AUTOSAR XML (schema 00049)
# Copyright (c) 2018 Vector Informatik GmbH.
standard types defined: boolean, uint16, uint32, uint8
package /VehicleProject
  system System
package /TP
  lin tp config LINISO17987: communication-cluster=LINISO17987
    tp address TA_0x0002: tp-address=2
    tp address TA_0x0003: tp-address=3
    tp address TA_0x007E: tp-address=126
    tp-connections:
      data-pdu=MasterReq_Tp, lin-tp-n-sdu=MasterReq, multicast=TA_0x007E, receiver=[TN_0x0002_Motor1, TN_0x0003_Motor2], transmitter=TN_Master
      data-pdu=SlaveResp_Tp, flow-control=MasterReq_Tp, lin-tp-n-sdu=SlaveResp_Motor1, receiver=TN_Master, transmitter=TN_0x0002_Motor1
      data-pdu=SlaveResp_Tp, flow-control=MasterReq_Tp, lin-tp-n-sdu=SlaveResp_Motor2, receiver=TN_Master, transmitter=TN_0x0003_Motor2
      data-pdu=MasterReq_Tp, flow-control=SlaveResp_Tp, lin-tp-n-sdu=MasterReq_Motor1, receiver=TN_0x0002_Motor1, transmitter=TN_Master
      data-pdu=MasterReq_Tp, flow-control=SlaveResp_Tp, lin-tp-n-sdu=MasterReq_Motor2, receiver=TN_0x0003_Motor2, transmitter=TN_Master
    lin tp node TN_0x0002_Motor1: connector=Motor1/CN_LINISO17987, tp-address=TA_0x0002
    lin tp node TN_0x0003_Motor2: connector=Motor2/CN_LINISO17987, tp-address=TA_0x0003
    lin tp node TN_Master: connector=SeatECU/CN_LINISO17987
package /Cluster
  lin cluster LINISO17987: baudrate=19200, protocol-name=LIN, protocol-version=ISO17987  # /*************************************************************************************/ // // Description: LIN Description file created using Vector's DaVinci Network Designer // Created: 07 Sep 2007 14:37:29 // Author: Vector Informatik GmbH // Version: 0.1 // /*************************************************************************************/
    lin physical channel CHNL: comm-connectors=[Motor1/CN_LINISO17987, Motor2/CN_LINISO17987, SeatECU/CN_LINISO17987]
      frame ETF_MotorStates: id 0x3A, from Motor1 Motor2, to SeatECU, frame-length=3, collision-resolving-schedule=ETFCollisionResolving, lin-unconditional-frame=[Motor1State_Event, Motor2State_Event], lin-checksum=ENHANCED
      frame MasterReq: id 0x3C, from SeatECU, to Motor1 Motor2, frame-length=8, lin-checksum=CLASSIC
        n pdu MasterReq_Tp: length=8
      frame Motor1Control: id 0x30, from SeatECU, to Motor1, frame-length=1, lin-checksum=ENHANCED
        pdu Motor1Control: length=1, transmission-mode-true-timing=event-controlled-timing={number-of-repetitions=0, repetition-period=0}, unused-bit-pattern=255
          signal Motor1Selection_oMotor1Control: start 0, 2 bit, little-endian, i-signal-type=PRIMITIVE, init-value=0, base-type=uint8, compu {identical}, range raw 0..3, transfer-property=TRIGGERED-WITHOUT-REPETITION, to Motor1
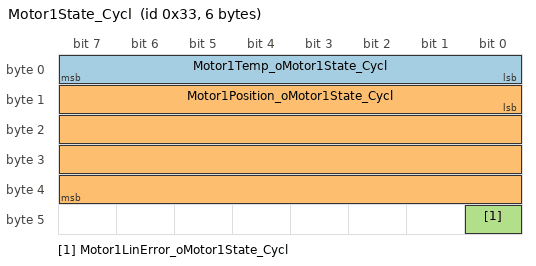
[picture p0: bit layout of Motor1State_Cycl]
      frame Motor1State_Cycl: id 0x33, from Motor1, to SeatECU, frame-length=6, lin-checksum=ENHANCED
        pdu Motor1State_Cycl: length=6, unused-bit-pattern=255
          signal Motor1Temp_oMotor1State_Cycl: start 0, 8 bit, little-endian, i-signal-type=PRIMITIVE, init-value=5, base-type=uint8, compu {phys=raw*0.5-20 for raw 0..80; unit Degree}, range raw 0..80, unit=Degree, to SeatECU
          signal Motor1Position_oMotor1State_Cycl: start 8, 32 bit, little-endian, i-signal-type=PRIMITIVE, init-value=0, base-type=uint32, compu {identical}, range raw 0..4294967295, to SeatECU
          signal Motor1LinError_oMotor1State_Cycl: start 40, 1 bit, little-endian, i-signal-type=PRIMITIVE, init-value=0, base-type=boolean, compu {identical}, range raw 0..1, to SeatECU
      frame Motor1State_Event: id 0x36, from Motor1, to SeatECU, frame-length=3, lin-checksum=ENHANCED
        pdu Motor1State_Event: length=3, unused-bit-pattern=255
          signal Motor1ErrorCode_oMotor1State_Event: start 8, 8 bit, little-endian, i-signal-type=PRIMITIVE, init-value=5, base-type=uint8, compu {identical}, range raw 0..255, to SeatECU
          signal Motor1ErrorValue_oMotor1State_Event: start 16, 8 bit, little-endian, i-signal-type=PRIMITIVE, init-value=1, base-type=uint8, compu {identical}, range raw 0..255, to SeatECU
      frame Motor2Control: id 0x31, from SeatECU, to Motor2, frame-length=1, lin-checksum=ENHANCED
        pdu Motor2Control: length=1, transmission-mode-true-timing=event-controlled-timing={number-of-repetitions=0, repetition-period=0}, unused-bit-pattern=255
          signal Motor2Selection_oMotor2Control: start 0, 2 bit, little-endian, i-signal-type=PRIMITIVE, init-value=0, base-type=uint8, compu {identical}, range raw 0..3, transfer-property=TRIGGERED-WITHOUT-REPETITION, to Motor2
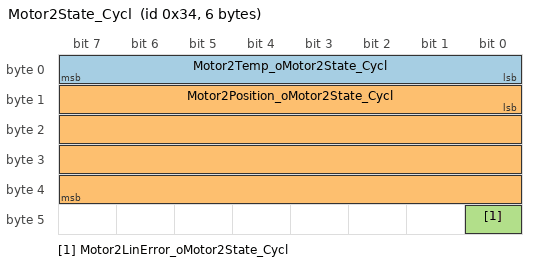
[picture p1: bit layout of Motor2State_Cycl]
      frame Motor2State_Cycl: id 0x34, from Motor2, to SeatECU, frame-length=6, lin-checksum=ENHANCED
        pdu Motor2State_Cycl: length=6, unused-bit-pattern=255
          signal Motor2Temp_oMotor2State_Cycl: start 0, 8 bit, little-endian, i-signal-type=PRIMITIVE, init-value=0, base-type=uint8, compu {phys=raw*0.5-20 for raw 0..80; unit Degree}, range raw 0..80, unit=Degree, to SeatECU
          signal Motor2Position_oMotor2State_Cycl: start 8, 32 bit, little-endian, i-signal-type=PRIMITIVE, init-value=0, base-type=uint32, compu {identical}, range raw 0..4294967295, to SeatECU
          signal Motor2LinError_oMotor2State_Cycl: start 40, 1 bit, little-endian, i-signal-type=PRIMITIVE, init-value=0, base-type=boolean, compu {identical}, range raw 0..1, to SeatECU
      frame Motor2State_Event: id 0x37, from Motor2, to SeatECU, frame-length=3, lin-checksum=ENHANCED
        pdu Motor2State_Event: length=3, unused-bit-pattern=255
          signal Motor2ErrorCode_oMotor2State_Event: start 8, 8 bit, little-endian, i-signal-type=PRIMITIVE, init-value=2, base-type=uint8, compu {identical}, range raw 0..255, to SeatECU
          signal Motor2ErrorValue_oMotor2State_Event: start 16, 8 bit, little-endian, i-signal-type=PRIMITIVE, init-value=4, base-type=uint8, compu {identical}, range raw 0..255, to SeatECU
      frame MotorsControl: id 0x2D, from SeatECU, to Motor1 Motor2, frame-length=2, lin-checksum=ENHANCED
        pdu MotorsControl: length=2, unused-bit-pattern=255
          signal MotorDirection_oMotorsControl: start 0, 2 bit, little-endian, i-signal-type=PRIMITIVE, init-value=0, base-type=uint8, compu {identical}, range raw 0..3, to Motor1 Motor2
          signal MotorSpeed_oMotorsControl: start 2, 10 bit, little-endian, i-signal-type=PRIMITIVE, init-value=0, base-type=uint16, compu {identical}, range raw 0..1023, unit=rpm, to Motor1 Motor2
      frame SlaveResp: id 0x3D, from Motor1 Motor2, to SeatECU, frame-length=8, lin-checksum=CLASSIC
        n pdu SlaveResp_Tp: length=8
      frame SporadicControlFrame: from SeatECU, to Motor1 Motor2, frame-length=1, substituted-frame=[Motor1Control, Motor2Control]
      pdu triggering PT_MasterReq: pdu=MasterReq, from SeatECU, to Motor1 Motor2
      pdu triggering PT_MasterReq_Motor1: pdu=MasterReq_Motor1, from SeatECU, to Motor1
      pdu triggering PT_MasterReq_Motor2: pdu=MasterReq_Motor2, from SeatECU, to Motor2
      pdu triggering PT_SlaveResp_Motor1: pdu=SlaveResp_Motor1, from Motor1, to SeatECU
      pdu triggering PT_SlaveResp_Motor2: pdu=SlaveResp_Motor2, from Motor2, to SeatECU
      5 x lin schedule table, all with run-mode=RUN-CONTINUOUS:
        NormalTable
          table-entrys:
            delay=0.05, position-in-table=0, frame-triggering=FT_MotorsControl
            delay=0.05, position-in-table=1, frame-triggering=FT_Motor1State_Cycl
            delay=0.05, position-in-table=2, frame-triggering=FT_Motor2State_Cycl
            delay=0.05, position-in-table=3, frame-triggering=FT_ETF_MotorStates
            delay=0.02, position-in-table=4, frame-triggering=FT_SporadicControlFrame
        ETFCollisionResolving
          table-entrys:
            delay=0.05, position-in-table=0, frame-triggering=FT_Motor1State_Event
            delay=0.05, position-in-table=1, frame-triggering=FT_Motor2State_Event
        InitTable: table-entrys={assign-nad={delay=0.01, position-in-table=0, assigned-controller=Motor1/CT_LINISO17987, new-nad=2}, application-entry={delay=0.01, position-in-table=1, frame-triggering=FT_SlaveResp}, assign-nad={delay=0.01, position-in-table=2, assigned-controller=Motor2/CT_LINISO17987, new-nad=3}, application-entry={delay=0.01, position-in-table=3, frame-triggering=FT_SlaveResp}, assign-frame-id-range={delay=0.01, position-in-table=4, assigned-controller=Motor1/CT_LINISO17987, frame-pids=[{index=0, pid=173}, {index=1, pid=240}, {index=2, pid=115}, {index=3, pid=118}], start-index=0}, assign-frame-id-range={delay=0.01, position-in-table=5, assigned-controller=Motor1/CT_LINISO17987, frame-pids=[{index=4, pid=186}, {index=5, pid=255}, {index=6, pid=255}, {index=7, pid=255}], start-index=4}, assign-frame-id-range={delay=0.01, position-in-table=6, assigned-controller=Motor2/CT_LINISO17987, frame-pids=[{index=0, pid=173}, {index=1, pid=177}, {index=2, pid=180}, {index=3, pid=55}], start-index=0}, assign-frame-id-range={delay=0.01, position-in-table=7, assigned-controller=Motor2/CT_LINISO17987, frame-pids=[{index=4, pid=186}, {index=5, pid=255}, {index=6, pid=255}, {index=7, pid=255}], start-index=4}}
        MasterReqTable: application-entry{delay=0.01, position-in-table=0, frame-triggering=FT_MasterReq}
        SlaveRespTable: application-entry{delay=0.01, position-in-table=0, frame-triggering=FT_SlaveResp}
package /ECU
  ecu instance Motor1: associated-com-i-pdu-group=[Motor1_Rx, Motor1_Tx]
    lin slave CT_LINISO17987: protocol-version=ISO17987, assign-nad=false, configured-nad=2, function-id=1, initial-nad=10, lin-error-response=ST_Motor1LinError_oMotor1State_Cycl, nas-timeout=1000, supplier-id=30, variant-id=0
    lin communication connector CN_LINISO17987: comm-controller=Motor1/CT_LINISO17987, initial-nad=10
      lin-ordered-configurable-frames:
        frame=MotorsControl, index=0
        frame=Motor1Control, index=1
        frame=Motor1State_Cycl, index=2
        frame=Motor1State_Event, index=3
        frame=ETF_MotorStates, index=4
  ecu instance Motor2: associated-com-i-pdu-group=[Motor2_Rx, Motor2_Tx]
    lin slave CT_LINISO17987: protocol-version=ISO17987, assign-nad=false, configured-nad=3, function-id=11, initial-nad=12, lin-error-response=ST_Motor2LinError_oMotor2State_Cycl, nas-timeout=1000, supplier-id=46, variant-id=1
    lin communication connector CN_LINISO17987: comm-controller=Motor2/CT_LINISO17987, initial-nad=12
      lin-ordered-configurable-frames:
        frame=MotorsControl, index=0
        frame=Motor2Control, index=1
        frame=Motor2State_Cycl, index=2
        frame=Motor2State_Event, index=3
        frame=ETF_MotorStates, index=4
  ecu instance SeatECU: associated-com-i-pdu-group=[SeatECU_Rx, SeatECU_Tx]
    lin master CT_LINISO17987: protocol-version=ISO17987, time-base=0.005, time-base-jitter=0.0001
    lin communication connector CN_LINISO17987: comm-controller=CT_LINISO17987
package /IPDUGroup
  6 x i signal i pdu group:
    Motor1_Rx: communication-direction=IN, i-signal-i-pdus=[Motor1Control, MotorsControl]
    Motor1_Tx: communication-direction=OUT, i-signal-i-pdus=[Motor1State_Cycl, Motor1State_Event]
    Motor2_Rx: communication-direction=IN, i-signal-i-pdus=[Motor2Control, MotorsControl]
    Motor2_Tx: communication-direction=OUT, i-signal-i-pdus=[Motor2State_Cycl, Motor2State_Event]
    SeatECU_Rx: communication-direction=IN, i-signal-i-pdus=[Motor1State_Cycl, Motor1State_Event, Motor2State_Cycl, Motor2State_Event]
    SeatECU_Tx: communication-direction=OUT, i-signal-i-pdus=[Motor1Control, Motor2Control, MotorsControl]
package /PDU
  dcm i pdu MasterReq_Motor1: length=8, diag-pdu-type=DIAG-REQUEST
  dcm i pdu MasterReq_Motor2: length=8, diag-pdu-type=DIAG-REQUEST
  dcm i pdu MasterReq: length=8, diag-pdu-type=DIAG-REQUEST
  dcm i pdu SlaveResp_Motor1: length=8, diag-pdu-type=DIAG-RESPONSE
  dcm i pdu SlaveResp_Motor2: length=8, diag-pdu-type=DIAG-RESPONSE
package /DataType/Unit
  unit U_Degree: display-name=Degree
  unit U_rpm: display-name=rpm
package /Signal
  16 x system signal, all with compu {identical}, range raw 0..255:
    MasterReqB{0..7}
    SlaveRespB{0..7}
